# MSP430F2619 register map
Vendor: msp430gen; File version: v0.4.0
Registers are 8-bit, read-write, reset 0x0 unless marked. A register's access mark holds for its fields unless they carry their own. Offsets are from the block's base; [hi:lo] are bit positions; {n}, {i} and the like mark numbered series.

## USCI_A1_SPI_MODE
Base 0x000000D0
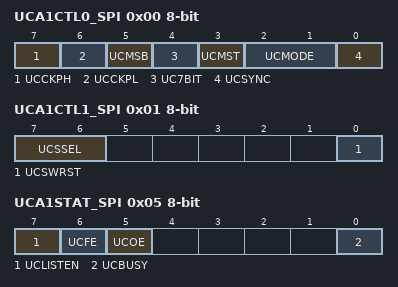
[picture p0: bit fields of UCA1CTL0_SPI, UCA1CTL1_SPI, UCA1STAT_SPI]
0x00 UCA1CTL0_SPI — USCI A1 Control Register 0
  [7] UCCKPH — Sync. Mode: Clock Phase
  [6] UCCKPL — Sync. Mode: Clock Polarity
  [5] UCMSB — Sync. Mode: MSB first 0:LSB / 1:MSB
  [4] UC7BIT — Sync. Mode: Data Bits 0:8-bits / 1:7-bits
  [3] UCMST — Sync. Mode: Master Select
  [2:1] UCMODE — Sync. Mode: USCI Mode 1
    {v}=Sync. Mode: USCI Mode: {v} (v=0..3)
  [0] UCSYNC — Sync-Mode 0:UART-Mode / 1:SPI-Mode
0x01 UCA1CTL1_SPI — USCI A1 Control Register 1
  [7:6] UCSSEL — USCI 1 Clock Source Select 1
    {v}=USCI 0 Clock Source: {v} (v=0..3)
  [0] UCSWRST — USCI Software Reset
0x02 UCA1BR0_SPI — USCI A1 Baud Rate 0
0x03 UCA1BR1_SPI — USCI A1 Baud Rate 1
0x04 UCA1MCTL_SPI — USCI A1 Modulation Control
0x05 UCA1STAT_SPI — USCI A1 Status Register
  [7] UCLISTEN — USCI Listen mode
  [6] UCFE — USCI Frame Error Flag
  [5] UCOE — USCI Overrun Error Flag
  [0] UCBUSY — USCI Busy Flag
0x06 UCA1RXBUF_SPI — USCI A1 Receive Buffer
0x07 UCA1TXBUF_SPI — USCI A1 Transmit Buffer

## USCI_B1_I2C_MODE
Base 0x000000D8
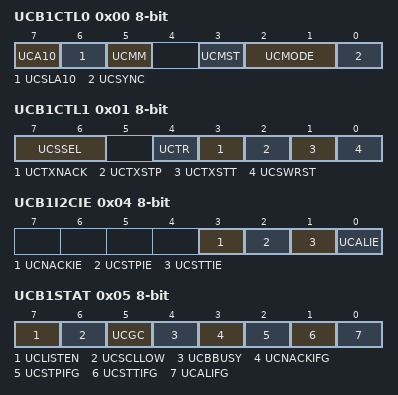
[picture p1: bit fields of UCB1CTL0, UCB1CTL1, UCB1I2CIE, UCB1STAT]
0x00 UCB1CTL0 — USCI B1 Control Register 0
  [7] UCA10 — 10-bit Address Mode
  [6] UCSLA10 — 10-bit Slave Address Mode
  [5] UCMM — Multi-Master Environment
  [3] UCMST — Sync. Mode: Master Select
  [2:1] UCMODE — Sync. Mode: USCI Mode 1
    {v}=Sync. Mode: USCI Mode: {v} (v=0..3)
  [0] UCSYNC — Sync-Mode 0:UART-Mode / 1:SPI-Mode
0x01 UCB1CTL1 — USCI B1 Control Register 1
  [7:6] UCSSEL — USCI 1 Clock Source Select 1
    {v}=USCI 0 Clock Source: {v} (v=0..3)
  [4] UCTR — Transmit/Receive Select/Flag
  [3] UCTXNACK — Transmit NACK
  [2] UCTXSTP — Transmit STOP
  [1] UCTXSTT — Transmit START
  [0] UCSWRST — USCI Software Reset
0x02 UCB1BR0 — USCI B1 Baud Rate 0
0x03 UCB1BR1 — USCI B1 Baud Rate 1
0x04 UCB1I2CIE — USCI B1 I2C Interrupt Enable Register
  [3] UCNACKIE — NACK Condition interrupt enable
  [2] UCSTPIE — STOP Condition interrupt enable
  [1] UCSTTIE — START Condition interrupt enable
  [0] UCALIE — Arbitration Lost interrupt enable
0x05 UCB1STAT — USCI B1 Status Register
  [7] UCLISTEN — USCI Listen mode
  [6] UCSCLLOW — SCL low
  [5] UCGC — General Call address received Flag
  [4] UCBBUSY — Bus Busy Flag
  [3] UCNACKIFG — NAK Condition interrupt Flag
  [2] UCSTPIFG — STOP Condition interrupt Flag
  [1] UCSTTIFG — START Condition interrupt Flag
  [0] UCALIFG — Arbitration Lost interrupt Flag
0x06 UCB1RXBUF — USCI B1 Receive Buffer
0x07 UCB1TXBUF — USCI B1 Transmit Buffer
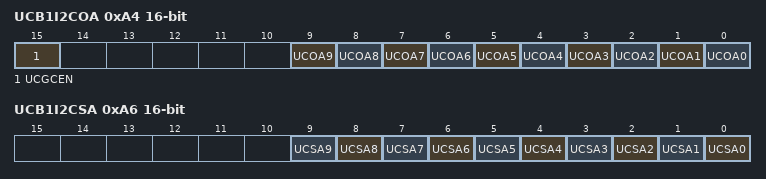
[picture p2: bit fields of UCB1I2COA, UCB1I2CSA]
0xA4 UCB1I2COA 16-bit — USCI B1 I2C Own Address
  [15] UCGCEN — I2C General Call enable
  [n] UCOA{n} (n=0..9) — I2C Own Address {n}
0xA6 UCB1I2CSA 16-bit — USCI B1 I2C Slave Address
  [n] UCSA{n} (n=0..9) — I2C Slave Address {n}

## USCI_B1_SPI_MODE
Base 0x000000D8
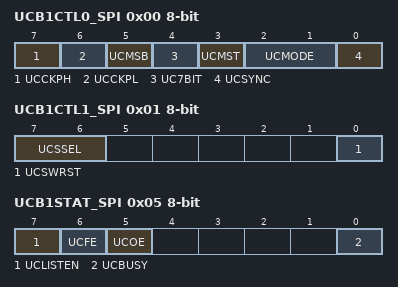
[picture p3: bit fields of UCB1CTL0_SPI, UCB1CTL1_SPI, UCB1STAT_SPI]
0x00 UCB1CTL0_SPI — USCI B1 Control Register 0
  [7] UCCKPH — Sync. Mode: Clock Phase
  [6] UCCKPL — Sync. Mode: Clock Polarity
  [5] UCMSB — Sync. Mode: MSB first 0:LSB / 1:MSB
  [4] UC7BIT — Sync. Mode: Data Bits 0:8-bits / 1:7-bits
  [3] UCMST — Sync. Mode: Master Select
  [2:1] UCMODE — Sync. Mode: USCI Mode 1
    {v}=Sync. Mode: USCI Mode: {v} (v=0..3)
  [0] UCSYNC — Sync-Mode 0:UART-Mode / 1:SPI-Mode
0x01 UCB1CTL1_SPI — USCI B1 Control Register 1
  [7:6] UCSSEL — USCI 1 Clock Source Select 1
    {v}=USCI 0 Clock Source: {v} (v=0..3)
  [0] UCSWRST — USCI Software Reset
0x02 UCB1BR0_SPI — USCI B1 Baud Rate 0
0x03 UCB1BR1_SPI — USCI B1 Baud Rate 1
0x05 UCB1STAT_SPI — USCI B1 Status Register
  [7] UCLISTEN — USCI Listen mode
  [6] UCFE — USCI Frame Error Flag
  [5] UCOE — USCI Overrun Error Flag
  [0] UCBUSY — USCI Busy Flag
0x06 UCB1RXBUF_SPI — USCI B1 Receive Buffer
0x07 UCB1TXBUF_SPI — USCI B1 Transmit Buffer

## TLV_CALIBRATION_DATA
Base 0x000010C0
0x00 TLV_CHECKSUM 16-bit
0x1A TLV_ADC12_1_TAG
0x1B TLV_ADC12_1_LEN
0x36 TLV_DCO_30_TAG — TLV TAG_DCO30 TAG
0x37 TLV_DCO_30_LEN — TLV TAG_DCO30 LEN
